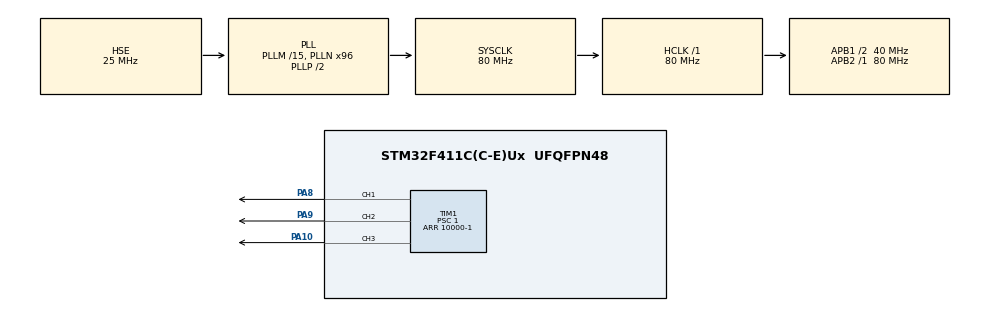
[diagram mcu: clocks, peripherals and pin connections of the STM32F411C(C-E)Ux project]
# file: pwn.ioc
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Dma.Request0=TIM1_UP
Dma.TIM1_UP.0.Direction=DMA_MEMORY_TO_PERIPH
Dma.TIM1_UP.0.FIFOMode=DMA_FIFOMODE_DISABLE
Dma.TIM1_UP.0.Instance=DMA2_Stream5
Dma.TIM1_UP.0.MemDataAlignment=DMA_MDATAALIGN_WORD
Dma.TIM1_UP.0.MemInc=DMA_MINC_ENABLE
Dma.TIM1_UP.0.Mode=DMA_CIRCULAR
Dma.TIM1_UP.0.PeriphDataAlignment=DMA_PDATAALIGN_WORD
Dma.TIM1_UP.0.PeriphInc=DMA_PINC_DISABLE
Dma.TIM1_UP.0.Priority=DMA_PRIORITY_LOW
Mcu.Family=STM32F4
Mcu.Name=STM32F411C(C-E)Ux
Mcu.Package=UFQFPN48
NVIC.DMA2_Stream5_IRQn=true\:0\:0\:false\:false\:true\:false\:true\:true
NVIC.PriorityGroup=NVIC_PRIORITYGROUP_4
PA10.Signal=S_TIM1_CH3
PA13.Mode=Serial_Wire
PA13.Signal=SYS_JTMS-SWDIO
PA14.Mode=Serial_Wire
PA14.Signal=SYS_JTCK-SWCLK
PA8.Signal=S_TIM1_CH1
PA9.Signal=S_TIM1_CH2
PH0\ -\ OSC_IN.Mode=HSE-External-Oscillator
PH0\ -\ OSC_IN.Signal=RCC_OSC_IN
PH1\ -\ OSC_OUT.Mode=HSE-External-Oscillator
PH1\ -\ OSC_OUT.Signal=RCC_OSC_OUT
ProjectManager.HeapSize=0x200
ProjectManager.StackSize=0x400
ProjectManager.TargetToolchain=STM32CubeIDE
RCC.48MHZClocksFreq_Value=40000000
RCC.AHBFreq_Value=80000000
RCC.APB1CLKDivider=RCC_HCLK_DIV2
RCC.APB1Freq_Value=40000000
RCC.APB1TimFreq_Value=80000000
RCC.APB2Freq_Value=80000000
RCC.APB2TimFreq_Value=80000000
RCC.CortexFreq_Value=80000000
RCC.HCLKFreq_Value=80000000
RCC.HSE_VALUE=25000000
RCC.HSI_VALUE=16000000
RCC.LSE_VALUE=32768
RCC.PLLM=15
RCC.PLLN=96
RCC.PLLSourceVirtual=RCC_PLLSOURCE_HSE
RCC.SYSCLKFreq_VALUE=80000000
RCC.SYSCLKSource=RCC_SYSCLKSOURCE_PLLCLK
RCC.VCOOutputFreq_Value=160000000
SH.S_TIM1_CH1.0=TIM1_CH1,PWM Generation1 CH1
SH.S_TIM1_CH2.0=TIM1_CH2,PWM Generation2 CH2
SH.S_TIM1_CH3.0=TIM1_CH3,PWM Generation3 CH3
STMicroelectronics.X-CUBE-ALGOBUILD.1.4.0.LibraryCcDSPOoLibraryJjDSPOoLibrary=true
TIM1.Channel-PWM\ Generation1\ CH1=TIM_CHANNEL_1
TIM1.Channel-PWM\ Generation2\ CH2=TIM_CHANNEL_2
TIM1.Channel-PWM\ Generation3\ CH3=TIM_CHANNEL_3
TIM1.OCMode_PWM-PWM\ Generation1\ CH1=TIM_OCMODE_PWM2
TIM1.OCMode_PWM-PWM\ Generation2\ CH2=TIM_OCMODE_PWM2
TIM1.OCMode_PWM-PWM\ Generation3\ CH3=TIM_OCMODE_PWM2
TIM1.Period=10000-1
TIM1.Prescaler=1
VP_STMicroelectronics.X-CUBE-ALGOBUILD_VS_DSPOoLibraryJjLibrary_1.4.0_1.4.0.Mode=DSPOoLibraryJjLibrary
VP_TIM1_VS_ClockSourceINT.Mode=Internal
board=custom

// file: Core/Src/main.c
/* USER CODE BEGIN Header */
/**
  ******************************************************************************
  * @file           : main.c
  * @brief          : Main program body
  ******************************************************************************
  * @attention
  *
  * Copyright (c) 2025 STMicroelectronics.
  * All rights reserved.
  *
  * This software is licensed under terms that can be found in the LICENSE file
  * in the root directory of this software component.
  * If no LICENSE file comes with this software, it is provided AS-IS.
  *
  ******************************************************************************
  */
/* USER CODE END Header */
#include "main.h"
#include "dma.h"
#include "tim.h"
#include "gpio.h"

/* USER CODE BEGIN Includes */
#include "arm_math.h"

/* USER CODE END Includes */

/* USER CODE BEGIN PV */
float32_t angle = 0U;
// #define PI 3.1415f
volatile uint32_t sindat[300] = {0,};
uint32_t uf = 5000U;

/* USER CODE END PV */

void SystemClock_Config(void);

int main(void)
{

  /* MCU Configuration--------------------------------------------------------*/

  /* Reset of all peripherals, Initializes the Flash interface and the Systick. */
  HAL_Init();

  /* Configure the system clock */
  SystemClock_Config();

  /* Initialize all configured peripherals */
  MX_GPIO_Init();
  MX_DMA_Init();
  MX_TIM1_Init();
  /* USER CODE BEGIN 2 */

  for (uint8_t i = 0; i<100; i++) { // опорная частота шим 4 кГц/50 Гц
  	  angle = i * 3.6f; // угол отсчета 360/80 в градусах
  	  // angle = i * 0.7853981f; // угол отсчета 2pi/80 в радианах
  	  // sindat[3 * i] = uf + uf * arm_sin_f32(angle);
  	  sindat[3 * i] = (uint32_t) (uf + uf * arm_sin_f32((angle * PI)/180));
  }

  	  // фаза Б
  for (uint8_t i = 0; i<100; i++) { // опорная частота шим 4 кГц/50 Гц
    	  angle = i * 3.6f + 120; // угол отсчета 360/80 в градусах
    	      	  sindat[(3 * i) + 1] = uf + uf * arm_sin_f32((angle * PI)/180);
    }

  // фаза С
    for (uint8_t i = 0; i<100; i++) { // опорная частота шим 4 кГц/50 Гц
      	  angle = i * 3.6f + 240; // угол отсчета 360/80 в градусах
      	      	  sindat[(3 * i) + 2] = uf + uf * arm_sin_f32((angle * PI)/180);
      }

HAL_TIM_DMABurst_MultiWriteStart(&htim1, TIM_DMABASE_CCR1, TIM_DMA_UPDATE, (uint32_t*)sindat, TIM_DMABURSTLENGTH_3TRANSFERS, 300);

HAL_TIM_PWM_Start(&htim1, TIM_CHANNEL_1);
HAL_TIM_PWM_Start(&htim1, TIM_CHANNEL_2);
HAL_TIM_PWM_Start(&htim1, TIM_CHANNEL_3);
//TIM1->CCR1 = 5000;
//TIM1->CCR2 = 5000;
//TIM1->CCR3 = 5000;

//HAL_TIM_PWM_Start(&htim1, TIM_CHANNEL_1);
//TIM1->CCR1 = 500;
//TIM1->ARR = 2000-1;
//TIM1->PSC = 49;
//__HAL_TIM_SET_COMPARE(&htim1, TIM_CHANNEL_1, 500);

  /* USER CODE END 2 */

  /* Infinite loop */
  while (1)
  {

  }
}

void SystemClock_Config(void)
{
  RCC_OscInitTypeDef RCC_OscInitStruct = {0};
  RCC_ClkInitTypeDef RCC_ClkInitStruct = {0};

  /** Configure the main internal regulator output voltage
  */
  __HAL_RCC_PWR_CLK_ENABLE();
  __HAL_PWR_VOLTAGESCALING_CONFIG(PWR_REGULATOR_VOLTAGE_SCALE1);

  /** Initializes the RCC Oscillators according to the specified parameters
  * in the RCC_OscInitTypeDef structure.
  */
  RCC_OscInitStruct.OscillatorType = RCC_OSCILLATORTYPE_HSE;
  RCC_OscInitStruct.HSEState = RCC_HSE_ON;
  RCC_OscInitStruct.PLL.PLLState = RCC_PLL_ON;
  RCC_OscInitStruct.PLL.PLLSource = RCC_PLLSOURCE_HSE;
  RCC_OscInitStruct.PLL.PLLM = 15;
  RCC_OscInitStruct.PLL.PLLN = 96;
  RCC_OscInitStruct.PLL.PLLP = RCC_PLLP_DIV2;
  RCC_OscInitStruct.PLL.PLLQ = 4;
  if (HAL_RCC_OscConfig(&RCC_OscInitStruct) != HAL_OK)
  {
    Error_Handler();
  }

  /** Initializes the CPU, AHB and APB buses clocks
  */
  RCC_ClkInitStruct.ClockType = RCC_CLOCKTYPE_HCLK|RCC_CLOCKTYPE_SYSCLK
                              |RCC_CLOCKTYPE_PCLK1|RCC_CLOCKTYPE_PCLK2;
  RCC_ClkInitStruct.SYSCLKSource = RCC_SYSCLKSOURCE_PLLCLK;
  RCC_ClkInitStruct.AHBCLKDivider = RCC_SYSCLK_DIV1;
  RCC_ClkInitStruct.APB1CLKDivider = RCC_HCLK_DIV2;
  RCC_ClkInitStruct.APB2CLKDivider = RCC_HCLK_DIV1;

  if (HAL_RCC_ClockConfig(&RCC_ClkInitStruct, FLASH_LATENCY_2) != HAL_OK)
  {
    Error_Handler();
  }
}

void Error_Handler(void)
{
  __disable_irq();
  while (1)
  {
  }
}
